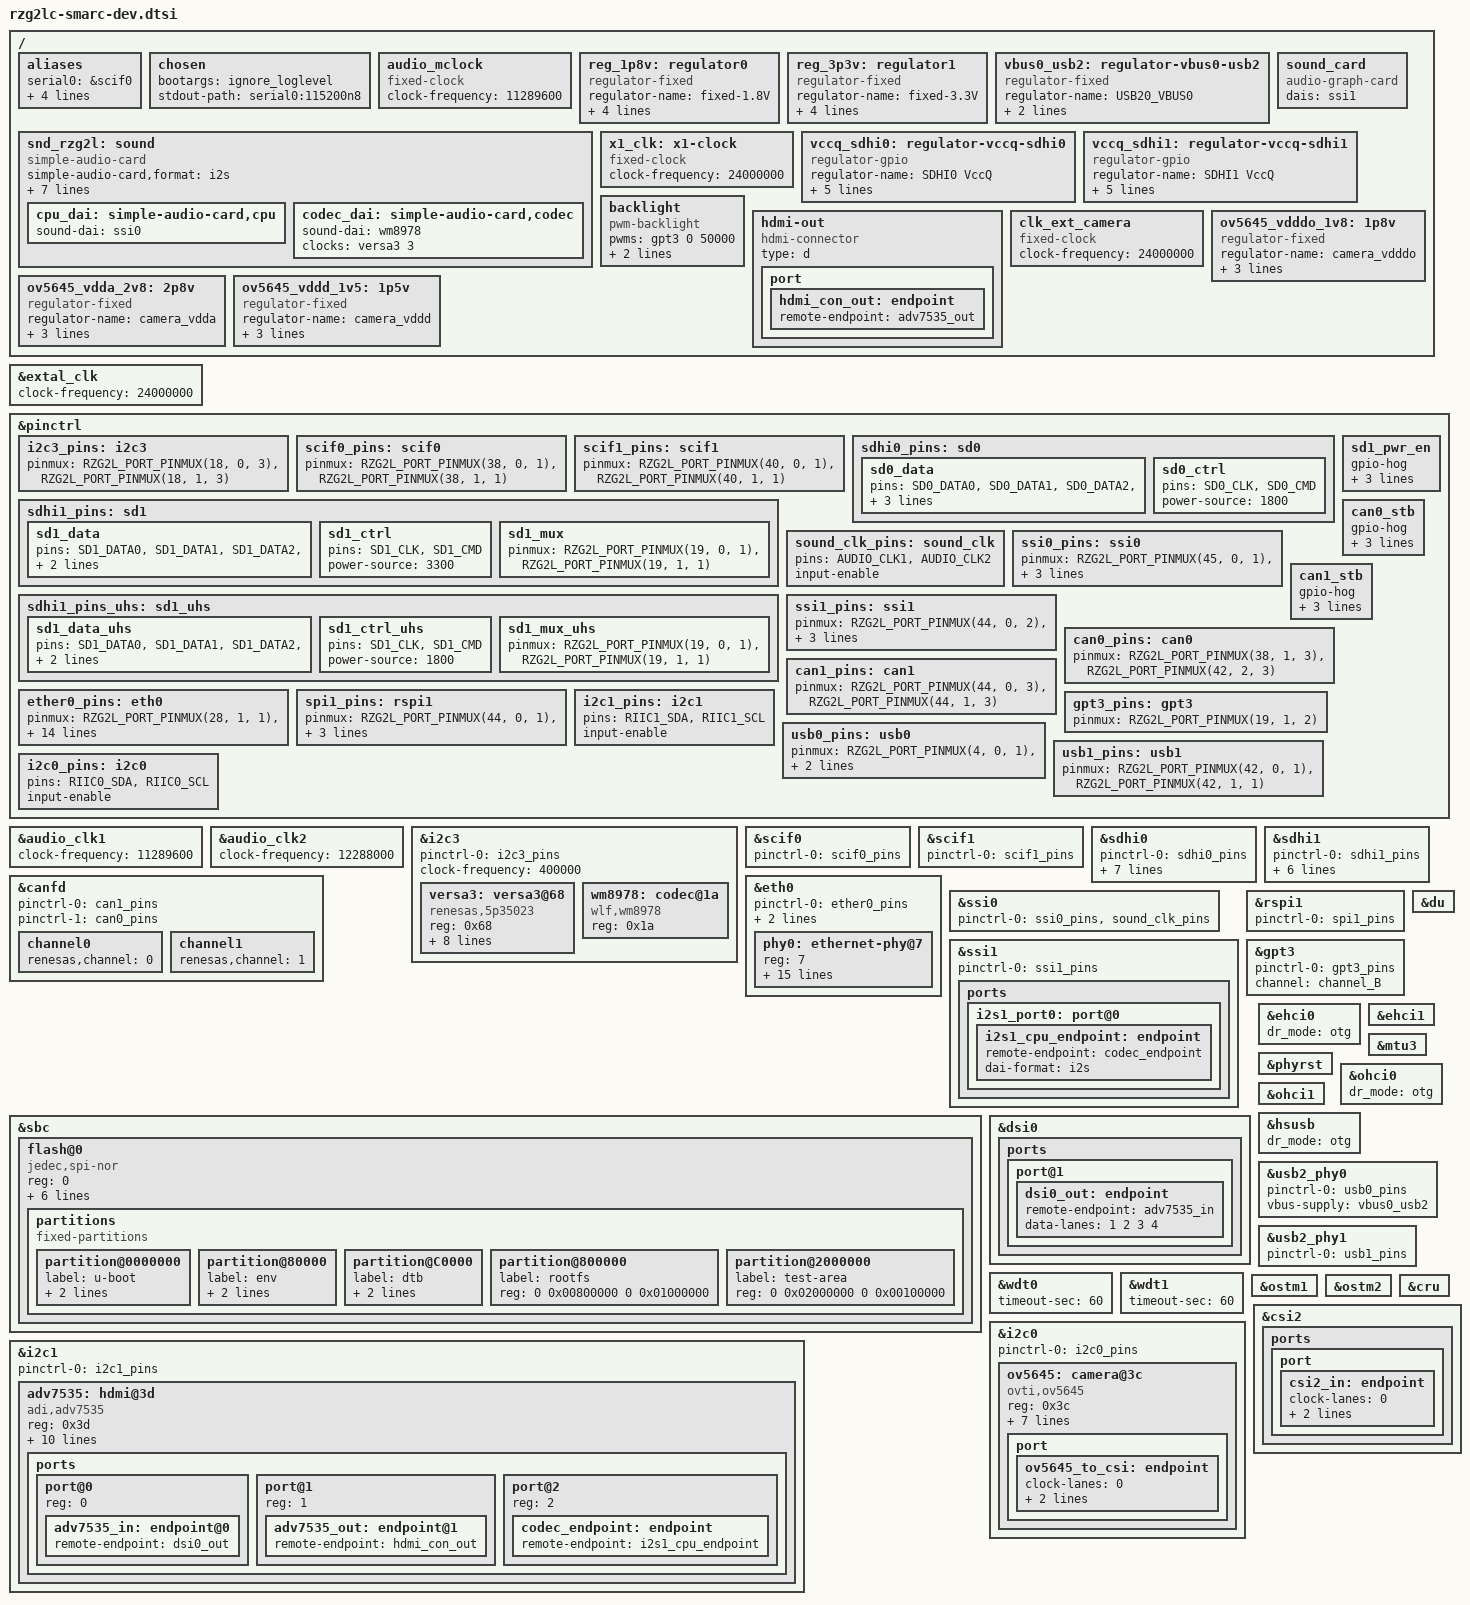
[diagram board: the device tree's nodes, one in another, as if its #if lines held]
// SPDX-License-Identifier: GPL-2.0
/*
 * Device Tree Source for the RZG2 SMARC main board common parts
 *
 * Copyright (C) 2020 Renesas Electronics Corp.
 */

#include <dt-bindings/pinctrl/rzg2l-pinctrl.h>
#include <dt-bindings/gpio/gpio.h>

/*
 * SSI-WM8978
 *
 * This command is required when Playback/Capture
 *
 *	amixer cset name='Left Input Mixer L2 Switch' on
 *	amixer cset name='Right Input Mixer R2 Switch' on
 *	amixer cset name='Headphone Playback Volume' 100
 *	amixer cset name='PCM Volume' 100%
 *	amixer cset name='Input PGA Volume' 25
 *
 * ADV7535 Audio playback
 *	aplay -D hw:1,0 xxx.wav
 */

/*
 * Jumper setting
 *
 * Please change the jumper setting coresponding to below Macros:
 * GPT3 OR SDHI1 selected by JP1.
 * CAN0 OR P42_2_CN_F and SCIF0 selected by JP2, JP30.
 * CAN1_STB OR PMOD03 selected by JP16.
 * CAN0_STB OR PMOD0 selected by JP38.
 * RIIC3 OR SD0(CD, WP) slected by JP28, JP29.
 * I2S1 OR RSPI1,CAN1 selected by JP33, JP34.
 * CAN1 OR RSPI1 selected by JP31, JP32.
 * SCIF1 selected by JP37.
 * JP1:  1: JP1-1  SD1_WP;         0: JP1-3  GTIOC3B
 * JP2:  1: JP2-1  CAN0_RX;        0: JP2-3  P42_2_CN_F
 * JP16: 1: JP16-1 P42_3_CAN1_STB; 0: JP16-3 P42_3_PMOD0_3
 * JP38: 1: JP38-1 P42_4_CAN0_STB; 0: JP38-3 P42_4_PMOD0
 * JP28: 1: JP28-1 IIC3_SDA;       0: JP28-3 SD0_CD_33
 * JP29: 1: JP29-1 IIC3_SDA;       0: JP29-3 SD0_WP_33
 * JP33: 1: JP33-1 I2S1_CK;        0: JP33-3 (RSPI1_CK|CAN1_TX)
 * JP34: 1: JP34-1 I2S1_LRCK;      0: JP34-3 (RSPI1_MOSI|CAN1_RX)
 * JP32: 1: JP32-1 RSPI1_CK;       0: JP32-3 CAN1_TX
 * JP31: 1: JP31-1 RSPI1_MOSI;     0: JP31-3 CAN1_RX
 * JP30: 1: JP30-1 SCIF0_RXD;      0: JP30-3 CAN0_TX
 * JP37: 1: JP37-1 85305-0232;     0: JP37-3 SCIF1_TXD
 *
 */

#define JP1	1
#define JP2	0
#define JP16	1
#define JP38	1
#define JP28 	1
#define JP29	1
#define JP33	0
#define JP32	0
#define JP34	0
#define JP31	0
#define JP30	1
#define JP37	0

/*
 * Select one output interface for MIPI DSI.
 * Support HDMI will be set by default.
 * Only one can be enabled at once
 */
#define DISP_DSI_HDMI		1
//#define DISP_DSI_PANEL	1

#if (DISP_DSI_HDMI & DISP_DSI_PANEL)
#error "RZ/G2LC can only display 1 output interface for MIPI DSI"
#endif

/ {
	aliases {
#if (JP30)
		serial0 = &scif0;
#endif

#if !(JP37)
		serial1 = &scif1;
#endif

#if (JP30 == 0 && JP2 == 1)
		can0 = &canfd;
#endif

#if (JP31 == 0 & JP32 == 0 & JP33 == 0 & JP34 == 0)
		can1 = &canfd;
#endif
		ethernet0 = &eth0;
	};

	chosen {
		bootargs = "ignore_loglevel";
		stdout-path = "serial0:115200n8";
	};

	audio_mclock: audio_mclock {
		compatible = "fixed-clock";
		#clock-cells = <0>;
		clock-frequency = <11289600>;
	};

	reg_1p8v: regulator0 {
		compatible = "regulator-fixed";

		regulator-name = "fixed-1.8V";
		regulator-min-microvolt = <1800000>;
		regulator-max-microvolt = <1800000>;
		regulator-boot-on;
		regulator-always-on;
	};

	reg_3p3v: regulator1 {
		compatible = "regulator-fixed";

		regulator-name = "fixed-3.3V";
		regulator-min-microvolt = <3300000>;
		regulator-max-microvolt = <3300000>;
		regulator-boot-on;
		regulator-always-on;
	};

	vbus0_usb2: regulator-vbus0-usb2 {
		compatible = "regulator-fixed";

		regulator-name = "USB20_VBUS0";
		regulator-min-microvolt = <5000000>;
		regulator-max-microvolt = <5000000>;
	};

#if (JP28 & JP29)
	snd_rzg2l: sound {
		compatible = "simple-audio-card";
		simple-audio-card,format = "i2s";
		simple-audio-card,bitclock-master = <&cpu_dai>;
		simple-audio-card,frame-master = <&cpu_dai>;
		simple-audio-card,mclk-fs = <256>;

		simple-audio-card,widgets = "Microphone", "Microphone Jack";
		simple-audio-card,routing =
			    "L2", "Mic Bias",
			    "R2", "Mic Bias",
			    "Mic Bias", "Microphone Jack";

		cpu_dai: simple-audio-card,cpu {
			sound-dai = <&ssi0>;
		};

		codec_dai: simple-audio-card,codec {
			sound-dai = <&wm8978>;
			clocks = <&versa3 3>;
		};
	};
#endif

	x1_clk: x1-clock {
		compatible = "fixed-clock";
		#clock-cells = <0>;
		clock-frequency = <24000000>;
	};

#if (JP33 == 1 & JP34 == 1)
	sound_card {
		compatible = "audio-graph-card";
		dais = <&ssi1>;
	};
#endif

	vccq_sdhi0: regulator-vccq-sdhi0 {
		compatible = "regulator-gpio";

		regulator-name = "SDHI0 VccQ";
		regulator-min-microvolt = <1800000>;
		regulator-max-microvolt = <3300000>;

		gpios = <&pinctrl RZG2L_GPIO(39, 0) GPIO_ACTIVE_HIGH>;

		gpios-states = <1>;
		states = <3300000 0
			  1800000 1>;
	};

	vccq_sdhi1: regulator-vccq-sdhi1 {
		compatible = "regulator-gpio";

		regulator-name = "SDHI1 VccQ";
		regulator-min-microvolt = <1800000>;
		regulator-max-microvolt = <3300000>;

		gpios = <&pinctrl RZG2L_GPIO(39, 1) GPIO_ACTIVE_HIGH>;

		gpios-states = <1>;
		states = <3300000 0
			  1800000 1>;
	};

/* Read Only File system in QSPI Example */
/* File System in XIP QSPI */
/* Remember, we'll be in QSPI XIP mode at this point */
/* Requires CONFIG_MTD_ROM=y */
	qspi@20000000 {
		compatible = "mtd-rom";
		//probe-type = "map_rom";
		probe-type = "direct-mapped";   // XIP from QSPI
		reg = <0 0x20000000 0 0x4000000>;   /* 64 MB*/
		bank-width = <4>;
		device-width = <1>;

		#address-cells = <1>;
		#size-cells = <1>;

		partition@800000 {
			label ="rootfs_xipcramfs";
			reg = <0x0800000 0x1000000>; /* 16MB @ 0x20800000 */
			read-only;
		};
	};

	backlight {
		compatible = "pwm-backlight";
		pwms = <&gpt3 0 50000>;

		brightness-levels = <0 2 8 16 32 64 128 255>;
		default-brightness-level = <6>;
	};

#if (DISP_DSI_HDMI)
	hdmi-out {
		compatible = "hdmi-connector";
		type = "d";

		port {
			hdmi_con_out: endpoint {
				remote-endpoint = <&adv7535_out>;
			};
		};
	};
#endif

	clk_ext_camera: clk_ext_camera {
		compatible = "fixed-clock";
		#clock-cells = <0>;
		clock-frequency = <24000000>;
	};

	ov5645_vdddo_1v8: 1p8v {
		compatible = "regulator-fixed";
		regulator-name = "camera_vdddo";
		regulator-min-microvolt = <1800000>;
		regulator-max-microvolt = <1800000>;
		regulator-always-on;
	};

	ov5645_vdda_2v8: 2p8v {
		compatible = "regulator-fixed";
		regulator-name = "camera_vdda";
		regulator-min-microvolt = <2800000>;
		regulator-max-microvolt = <2800000>;
		regulator-always-on;
	};

	ov5645_vddd_1v5: 1p5v {
		compatible = "regulator-fixed";
		regulator-name = "camera_vddd";
		regulator-min-microvolt = <1500000>;
		regulator-max-microvolt = <1500000>;
		regulator-always-on;
	};
};

&extal_clk {
	clock-frequency = <24000000>;
};

&pinctrl {
#if (JP28 & JP29)
	i2c3_pins: i2c3 {
		pinmux = <RZG2L_PORT_PINMUX(18, 0, 3)>, /* SDA */
			 <RZG2L_PORT_PINMUX(18, 1, 3)>; /* SCL */
	};
#endif

#if (JP30)
	scif0_pins: scif0 {
		pinmux = <RZG2L_PORT_PINMUX(38, 0, 1)>, /* TxD */
			 <RZG2L_PORT_PINMUX(38, 1, 1)>; /* RxD */
	};
#endif

#if !(JP37)
	scif1_pins: scif1 {
		pinmux = <RZG2L_PORT_PINMUX(40, 0, 1)>,	/* TxD */
			 <RZG2L_PORT_PINMUX(40, 1, 1)>;	/* RxD */
	};
#endif

#if (JP28 & JP29)
	/* Support pinctrl for MMC function of SDHI0*/
	sdhi0_pins: sd0 {
		sd0_data {
			pins =  "SD0_DATA0", "SD0_DATA1", "SD0_DATA2",
				"SD0_DATA3", "SD0_DATA4", "SD0_DATA5",
				"SD0_DATA6", "SD0_DATA7";
			power-source  = <1800>;
		};

		sd0_ctrl {
			pins = "SD0_CLK", "SD0_CMD";
			power-source = <1800>;
		};
	};
#else
	/* Support pinctrl for SD function of SDHI0 */
	sdhi0_pins: sd0 {
		sd0_data {
			pins =  "SD0_DATA0", "SD0_DATA1", "SD0_DATA2",
				"SD0_DATA3";
			power-source  = <3300>;
		};

		sd0_ctrl {
			pins = "SD0_CLK", "SD0_CMD";
			power-source = <3300>;
		};

		sd1_mux {
			pinmux = <RZG2L_PORT_PINMUX(19, 0, 1)>, /* CD */
				 <RZG2L_PORT_PINMUX(19, 1, 1)>; /* WP */
		};
	};

	sdhi0_pins_uhs: sd0_uhs {
		sd0_data_uhs {
			pins =	"SD0_DATA0", "SD0_DATA1", "SD0_DATA2",
				"SD0_DATA3";
			power-source  = <1800>;
		};

		sd1_ctrl_uhs {
			pins = "SD0_CLK", "SD0_CMD";
			power-source  = <1800>;
		};

		sd1_mux_uhs {
			pinmux = <RZG2L_PORT_PINMUX(19, 0, 1)>, /* CD */
				 <RZG2L_PORT_PINMUX(19, 1, 1)>; /* WP */
		};
	};

	sd0_pwr_en {
		gpio-hog;
		gpios = <RZG2L_GPIO(4, 1) GPIO_ACTIVE_HIGH>;
		output-high;
		line-name = "sd0_pwr_en";
	};
#endif

#if (JP1)
	sdhi1_pins: sd1 {
		sd1_data {
			pins =	"SD1_DATA0", "SD1_DATA1", "SD1_DATA2",
				"SD1_DATA3";
			power-source  = <3300>;
		};

		sd1_ctrl {
			pins = "SD1_CLK", "SD1_CMD";
			power-source  = <3300>;
		};

		sd1_mux {
			pinmux = <RZG2L_PORT_PINMUX(19, 0, 1)>, /* CD */
				 <RZG2L_PORT_PINMUX(19, 1, 1)>; /* WP */
		};
	};

	sdhi1_pins_uhs: sd1_uhs {
		sd1_data_uhs {
			pins =	"SD1_DATA0", "SD1_DATA1", "SD1_DATA2",
				"SD1_DATA3";
			power-source  = <1800>;
		};

		sd1_ctrl_uhs {
			pins = "SD1_CLK", "SD1_CMD";
			power-source  = <1800>;
		};

		sd1_mux_uhs {
			pinmux = <RZG2L_PORT_PINMUX(19, 0, 1)>, /* CD */
				 <RZG2L_PORT_PINMUX(19, 1, 1)>; /* WP */
		};
	};

	sd1_pwr_en {
		gpio-hog;
		gpios = <RZG2L_GPIO(39, 2) GPIO_ACTIVE_HIGH>;
		output-high;
		line-name = "sd1_pwr_en";
	};
#endif

	sound_clk_pins: sound_clk {
		pins = "AUDIO_CLK1", "AUDIO_CLK2";
		input-enable;
	};

	ssi0_pins: ssi0 {
		pinmux = <RZG2L_PORT_PINMUX(45, 0, 1)>, /* BCK */
			 <RZG2L_PORT_PINMUX(45, 1, 1)>, /* RCK */
			 <RZG2L_PORT_PINMUX(45, 2, 1)>, /* TXD */
			 <RZG2L_PORT_PINMUX(45, 3, 1)>; /* RXD */
	};

#if (JP33 == 1 & JP34 == 1)
	ssi1_pins: ssi1 {
		pinmux = <RZG2L_PORT_PINMUX(44, 0, 2)>, /* BCK */
			 <RZG2L_PORT_PINMUX(44, 1, 2)>, /* RCK */
			 <RZG2L_PORT_PINMUX(44, 2, 2)>, /* TXD */
			 <RZG2L_PORT_PINMUX(44, 3, 2)>; /* RXD */
	};
#endif

#if (JP38)
	can0_stb {
		gpio-hog;
		gpios = <RZG2L_GPIO(42, 2) GPIO_ACTIVE_LOW>;
		output-high;
		line-name = "can0_stb";
	};
#endif
#if (JP16)
	can1_stb {
		gpio-hog;
		gpios = <RZG2L_GPIO(42, 3) GPIO_ACTIVE_LOW>;
		output-high;
		line-name = "can1_stb";
	};
#endif

#if (JP30 == 0 && JP2 == 1)
	can0_pins: can0 {
		pinmux = <RZG2L_PORT_PINMUX(38, 1, 3)>, /* TX */
			 <RZG2L_PORT_PINMUX(42, 2, 3)>; /* RX */
	};
#endif

#if (JP31 == 0 & JP32 == 0 & JP33 == 0 & JP34 == 0)
	can1_pins: can1 {
		pinmux = <RZG2L_PORT_PINMUX(44, 0, 3)>, /* TX */
			 <RZG2L_PORT_PINMUX(44, 1, 3)>; /* RX */
	};
#endif

	ether0_pins: eth0 {
		pinmux = <RZG2L_PORT_PINMUX(28, 1, 1)>, /* ET0_LINKSTA */
			 <RZG2L_PORT_PINMUX(27, 1, 1)>, /* ET0_MDC */
			 <RZG2L_PORT_PINMUX(28, 0, 1)>, /* ET0_MDIO */
			 <RZG2L_PORT_PINMUX(20, 0, 1)>, /* ET0_TXC */
			 <RZG2L_PORT_PINMUX(20, 1, 1)>, /* ET0_TX_CTL */
			 <RZG2L_PORT_PINMUX(20, 2, 1)>, /* ET0_TXD0 */
			 <RZG2L_PORT_PINMUX(21, 0, 1)>, /* ET0_TXD1 */
			 <RZG2L_PORT_PINMUX(21, 1, 1)>, /* ET0_TXD2 */
			 <RZG2L_PORT_PINMUX(22, 0, 1)>, /* ET0_TXD3 */
			 <RZG2L_PORT_PINMUX(24, 0, 1)>, /* ET0_RXC */
			 <RZG2L_PORT_PINMUX(24, 1, 1)>, /* ET0_RX_CTL */
			 <RZG2L_PORT_PINMUX(25, 0, 1)>, /* ET0_RXD0 */
			 <RZG2L_PORT_PINMUX(25, 1, 1)>, /* ET0_RXD1 */
			 <RZG2L_PORT_PINMUX(26, 0, 1)>, /* ET0_RXD2 */
			 <RZG2L_PORT_PINMUX(26, 1, 1)>; /* ET0_RXD3 */
	};

#if (JP31 == 1 & JP32 == 1 & JP33 == 0 & JP34 == 0)
	spi1_pins: rspi1 {
		pinmux = <RZG2L_PORT_PINMUX(44, 0, 1)>, /* CK */
			 <RZG2L_PORT_PINMUX(44, 1, 1)>, /* MOSI */
			 <RZG2L_PORT_PINMUX(44, 2, 1)>, /* MISO */
			 <RZG2L_PORT_PINMUX(44, 3, 1)>; /* SSL */
	};
#endif

#if !(JP1)
	gpt3_pins: gpt3 {
		pinmux = <RZG2L_PORT_PINMUX(19, 1, 2)>; /* Channel B */
	};
#endif

	i2c1_pins: i2c1 {
		pins = "RIIC1_SDA", "RIIC1_SCL";
		input-enable;
	};

	usb0_pins: usb0 {
		pinmux = <RZG2L_PORT_PINMUX(4, 0, 1)>, /* VBUS */
			 <RZG2L_PORT_PINMUX(5, 0, 1)>, /* OVC */
			 <RZG2L_PORT_PINMUX(5, 1, 1)>; /* OTG_ID */
	};

	usb1_pins: usb1 {
		pinmux = <RZG2L_PORT_PINMUX(42, 0, 1)>, /* VBUS */
			 <RZG2L_PORT_PINMUX(42, 1, 1)>; /* OVC */
	};

	i2c0_pins: i2c0 {
		pins = "RIIC0_SDA", "RIIC0_SCL";
		input-enable;
	};
};

&audio_clk1{
	clock-frequency = <11289600>;
};

&audio_clk2{
	clock-frequency = <12288000>;
};

#if (JP28 & JP29)
&i2c3 {
	pinctrl-0 = <&i2c3_pins>;
	pinctrl-names = "default";

	status = "okay";
	clock-frequency = <400000>;

	versa3: versa3@68 {
		compatible = "renesas,5p35023";
		reg = <0x68>;
		#clock-cells = <1>;
		clocks = <&x1_clk>;
		clock-names = "x1";
		assigned-clocks = <&versa3 0>,
				   <&versa3 1>,
				   <&versa3 2>,
				   <&versa3 3>,
				   <&versa3 4>,
				   <&versa3 5>;
		assigned-clock-rates =	<12288000>, <25000000>,
					<12000000>, <11289600>,
					<11289600>, <24000000>;
		clock-divider-read-only = <1>, <1>, <1>, <1>, <1>;
		clock-flags = <2176>, <2176>, <2176>, <2052>, <2176>, <2048>;
	};

	wm8978: codec@1a {
		compatible = "wlf,wm8978";
		#sound-dai-cells = <0>;
		reg = <0x1a>;
	};
};
#endif

#if (JP30)
&scif0 {
	pinctrl-0 = <&scif0_pins>;
	pinctrl-names = "default";
	status = "okay";
};
#endif

#if !(JP37)
&scif1 {
	pinctrl-0 = <&scif1_pins>;
	pinctrl-names = "default";
	status = "okay";
};
#endif

#if (JP28 & JP29)
&sdhi0 {
	pinctrl-0 = <&sdhi0_pins>;
	pinctrl-1 = <&sdhi0_pins>;
	pinctrl-names = "default", "state_uhs";

	vmmc-supply = <&reg_3p3v>;
	vqmmc-supply = <&reg_1p8v>;
	bus-width = <8>;
	mmc-hs200-1_8v;
	non-removable;
	fixed-emmc-driver-type = <1>;
	status = "okay";
};
#else
&sdhi0 {
	pinctrl-0 = <&sdhi0_pins>;
	pinctrl-1 = <&sdhi0_pins_uhs>;
	pinctrl-names = "default", "state_uhs";

	vmmc-supply = <&reg_3p3v>;
	vqmmc-supply = <&vccq_sdhi0>;

	bus-width = <4>;
	sd-uhs-sdr50;
	sd-uhs-sdr104;
	status = "okay";
};
#endif

#if (JP1)
&sdhi1 {
	pinctrl-0 = <&sdhi1_pins>;
	pinctrl-1 = <&sdhi1_pins_uhs>;
	pinctrl-names = "default", "state_uhs";

	vmmc-supply = <&reg_3p3v>;
	vqmmc-supply = <&vccq_sdhi1>;

	bus-width = <4>;
	sd-uhs-sdr50;
	sd-uhs-sdr104;
	status = "okay";
};
#endif

#if (JP31 == 0 & JP32 == 0 & JP33 == 0 & JP34 == 0)
&canfd {
	pinctrl-0 = <&can1_pins>;
	pinctrl-names = "default","default";
	status = "okay";

#if (JP30 == 0 && JP2 == 1)
	pinctrl-1 = <&can0_pins>;

	channel0 {
		renesas,channel = <0>;
		status = "okay";
	};
#endif

	channel1 {
		renesas,channel = <1>;
		status = "okay";
	};
};
#endif

&eth0 {
	pinctrl-0 = <&ether0_pins>;
	pinctrl-names = "default";
	phy-handle = <&phy0>;
	phy-mode = "rgmii";
	status = "okay";

	phy0: ethernet-phy@7 {
		reg = <7>;
		rxc-skew-psec = <2400>;
		txc-skew-psec = <2400>;
		rxdv-skew-psec = <0>;
		txdv-skew-psec = <0>;
		rxd0-skew-psec = <0>;
		rxd1-skew-psec = <0>;
		rxd2-skew-psec = <0>;
		rxd3-skew-psec = <0>;
		txd0-skew-psec = <0>;
		txd1-skew-psec = <0>;
		txd2-skew-psec = <0>;
		txd3-skew-psec = <0>;

		interrupt-parent = <&pinctrl>;
		interrupts = <RZG2L_GPIO(0, 1) IRQ_TYPE_EDGE_FALLING>;
	};
};

/* Delete our XIP QSPI partitions from the top of this file. You would not have these for non-XIP systems */
/ {
	/delete-node/ qspi@20000000;
};

&ssi0 {
	pinctrl-0 = <&ssi0_pins &sound_clk_pins>;
	pinctrl-names = "default";

	status = "okay";
};

#if (JP33 == 1 & JP34 == 1)
&ssi1 {
	pinctrl-0 = <&ssi1_pins>;
	pinctrl-names = "default";

	status = "okay";
	ports {
		i2s1_port0: port@0 {
			i2s1_cpu_endpoint: endpoint {
				remote-endpoint = <&codec_endpoint>;
				dai-format = "i2s";
			};
		};
	};
};
#endif

&sbc {
	status = "okay";

	flash@0 {
		compatible = "jedec,spi-nor";
		reg = <0>;
		spi-max-frequency = <30000000>;

		spi-tx-bus-width = <1>;
		spi-rx-bus-width = <1>;

		/* SPI Mode 3 */
		spi-cpol;
		spi-cpha;
		m25p,fast-read;

		partitions {
			compatible = "fixed-partitions";
			#address-cells = <2>;
			#size-cells = <2>;

			partition@0000000 {
				label = "u-boot";
				reg = <0 0x00000000 0 0x80000>;
				read-only;
			};
			partition@80000 {
				label = "env";
				reg = <0 0x00080000 0 0x40000>;
				read-only;
			};
			partition@C0000 {
				label = "dtb";
				reg = <0 0x000C0000 0 0x40000>;
				read-only;
			};
			partition@800000 {
				label = "rootfs";
				/* 16MB @ 8MB offset in SPI Flash */
				reg = <0 0x00800000 0 0x01000000>;
			};
			partition@2000000 {
				label = "test-area";
				reg = <0 0x02000000 0 0x00100000>;
			};
		};
	};
};

#if (JP31 == 1 & JP32 == 1 & JP33 == 0 & JP34 == 0)
&rspi1 {
	pinctrl-0 = <&spi1_pins>;
	pinctrl-names = "default";
	status = "okay";
};
#endif

#if !(JP1)
&gpt3 {
	pinctrl-0 = <&gpt3_pins>;
	pinctrl-names = "default";
	channel="channel_B";
	//conflict pin with SD1 WP
	status = "okay";
};
#endif

&i2c1 {
	pinctrl-0 = <&i2c1_pins>;
	pinctrl-names = "default";

	status = "okay";

#if (DISP_DSI_HDMI)
	adv7535: hdmi@3d {
		compatible = "adi,adv7535";
		reg = <0x3d>;

		avdd-supply = <&reg_1p8v>;
		dvdd-supply = <&reg_1p8v>;
		pvdd-supply = <&reg_1p8v>;
		a2vdd-supply = <&reg_1p8v>;
		v3p3-supply = <&reg_3p3v>;
		v1p2-supply = <&reg_1p8v>;

		interrupt-parent = <&pinctrl>;
		interrupts = <RZG2L_GPIO(43, 1) IRQ_TYPE_EDGE_FALLING>;

		adi,dsi-lanes = <4>;
		#sound-dai-cells = <0>;

		ports {
			#address-cells = <1>;
			#size-cells = <0>;

			port@0 {
				reg = <0>;
				adv7535_in: endpoint@0 {
					remote-endpoint = <&dsi0_out>;
				};
			};

			port@1 {
				reg = <1>;
				adv7535_out: endpoint@1 {
					remote-endpoint = <&hdmi_con_out>;
				};
			};
#if (JP33 == 1 & JP34 == 1)
			port@2 {
				reg = <2>;
				codec_endpoint: endpoint {
					remote-endpoint = <&i2s1_cpu_endpoint>;
				};
			};
#endif
		};
	};
#endif
};

&du {
	status = "okay";
};

&dsi0 {
	status = "okay";

	ports {
		port@1 {
			dsi0_out: endpoint {
#if (DISP_DSI_HDMI)
				remote-endpoint = <&adv7535_in>;
				data-lanes = <1 2 3 4>;
#endif
			};
		};
	};
};

&ehci0 {
	dr_mode = "otg";
	status = "okay";
};

&ehci1 {
	status = "okay";
};

&mtu3 {
	status = "okay";
};

&phyrst {
	status = "okay";
};

&ohci0 {
	dr_mode = "otg";
	status = "okay";
};

&ohci1 {
	status = "okay";
};

&hsusb {
	dr_mode = "otg";
	status = "okay";
};

&usb2_phy0 {
	pinctrl-0 = <&usb0_pins>;
	pinctrl-names = "default";

	vbus-supply = <&vbus0_usb2>;
	status = "okay";
};

&usb2_phy1 {
	pinctrl-0 = <&usb1_pins>;
	pinctrl-names = "default";

	status = "okay";
};

&wdt0 {
	status = "okay";
	timeout-sec = <60>;
};

&wdt1 {
	status = "okay";
	timeout-sec = <60>;
};

&ostm1 {
	status = "okay";
};

&ostm2 {
	status = "okay";
};

&i2c0 {
	pinctrl-0 = <&i2c0_pins>;
	pinctrl-names = "default";

	status = "okay";

	ov5645: camera@3c {
		compatible = "ovti,ov5645";
		reg = <0x3c>;
		clock-names = "xclk";
		clocks = <&clk_ext_camera>;
		clock-frequency = <24000000>;
		vdddo-supply = <&ov5645_vdddo_1v8>;
		vdda-supply = <&ov5645_vdda_2v8>;
		vddd-supply = <&ov5645_vddd_1v5>;
		enable-gpios = <&pinctrl RZG2L_GPIO(41, 1) GPIO_ACTIVE_HIGH>;
		reset-gpios = <&pinctrl RZG2L_GPIO(40, 2) GPIO_ACTIVE_LOW>;

		port {
			ov5645_to_csi: endpoint {
				clock-lanes = <0>;
				data-lanes = <1 2>;
				remote-endpoint = <&csi2_in>;
			};
		};
	};
};

&cru {
	status = "okay";
};

&csi2 {
	status = "okay";

	ports {
		port {
			csi2_in: endpoint {
				clock-lanes = <0>;
				data-lanes = <1 2>;
				remote-endpoint = <&ov5645_to_csi>;
			};
		};
	};
};
